AUTOSAR XML (schema 4-3-0)
package /VehicleProject
  system System
    system mapping System_MPPNG
      data-mappings:
        data-element=PpDoorStateRearLeft.DeDoorState, system-signal=sig_State_RearLeftDoor
        data-element=PpDoorStateRearRight.DeDoorState, system-signal=sig_State_RearRightDoor
        data-element=PpLightStateRear.DeLightState, system-signal=sig_RearInteriorLight
    root-software-compositions:
      root sw composition prototype EcuSwComposition: software-composition=ECU_Composition
package /ECUCompositionTypes
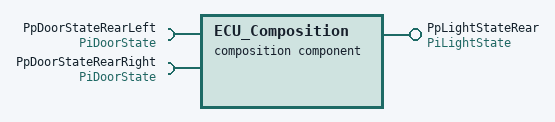
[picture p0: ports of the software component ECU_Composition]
  composition sw component type ECU_Composition
    require port PpDoorStateRearLeft: nonqueued-receiver-com-spec{data-element=DeDoorState, filter=data-filter-type=ALWAYS, init-value=0}, required-interface=PiDoorState
    require port PpDoorStateRearRight: nonqueued-receiver-com-spec{data-element=DeDoorState, filter=data-filter-type=ALWAYS, init-value=0}, required-interface=PiDoorState
    provide port PpLightStateRear: nonqueued-sender-com-spec{data-element=DeLightState, init-value=0}, provided-interface=PiLightState
    component CpCoApplication: type=CtCoApplication
    delegate CpCoApplication.PpDoorStateRearLeft <-> outer port PpDoorStateRearLeft
    delegate CpCoApplication.PpDoorStateRearRight <-> outer port PpDoorStateRearRight
    delegate CpCoApplication.PpLightStateRear <-> outer port PpLightStateRear
